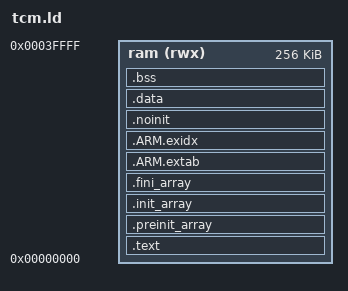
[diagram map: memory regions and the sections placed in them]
ENTRY(_start)

MEMORY {
	ram (rwx) : ORIGIN = 0, LENGTH = 256k
}

SECTIONS {
	.text : {
		*(.startup)
		*(.text*)	/* Program code */
		. = ALIGN(4);
		*(.rodata*)	/* Read-only data */
		. = ALIGN(4);
	} >ram

	/* C++ Static constructors/destructors, also used for
	 * __attribute__((constructor)) and the likes.
	 */
	.preinit_array : {
		. = ALIGN(4);
		__preinit_array_start = .;
		KEEP (*(.preinit_array))
		__preinit_array_end = .;
	} >ram
	.init_array : {
		. = ALIGN(4);
		__init_array_start = .;
		KEEP (*(SORT(.init_array.*)))
		KEEP (*(.init_array))
		__init_array_end = .;
	} >ram
	.fini_array : {
		. = ALIGN(4);
		__fini_array_start = .;
		KEEP (*(.fini_array))
		KEEP (*(SORT(.fini_array.*)))
		__fini_array_end = .;
	} >ram

	/*
	 * Another section used by C++ stuff, appears when using newlib with
	 * 64bit (long long) printf support
	 */
	.ARM.extab : {
		*(.ARM.extab*)
	} >ram
	.ARM.exidx : {
		__exidx_start = .;
		*(.ARM.exidx*)
		__exidx_end = .;
	} >ram

	. = ALIGN(4);
	_etext = .;

	/* ram, but not cleared on reset, eg boot/app comms */
	.noinit (NOLOAD) : {
		*(.noinit*)
	} >ram
	. = ALIGN(4);

	.data : {
		_data = .;
		*(.data*)	/* Read-write initialized data */
		*(.ramtext*)	/* "text" functions to run in ram */
		. = ALIGN(4);
		_edata = .;
	} >ram
	_data_loadaddr = LOADADDR(.data);

	.bss : {
		*(.bss*)	/* Read-write zero initialized data */
		*(COMMON)
		. = ALIGN(4);
		_ebss = .;
	} >ram

	/*
	 * The .eh_frame section appears to be used for C++ exception handling.
	 * You may need to fix this if you're using C++.
	 */
	/DISCARD/ : { *(.eh_frame) }

	. = ALIGN(4);
	end = .;
}

PROVIDE(_stack_sys = ORIGIN(ram) + LENGTH(ram) - 0x4000);
PROVIDE(_stack_irq = ORIGIN(ram) + LENGTH(ram));
